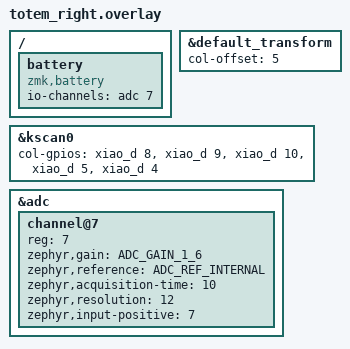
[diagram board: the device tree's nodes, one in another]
/*
 * Copyright (c) 2022 The ZMK Contributors
 *
 * SPDX-License-Identifier: MIT
 */

#include "totem.dtsi"

&default_transform {
    col-offset = <5>;
};

&kscan0 {
    col-gpios
        = <&xiao_d 8 GPIO_ACTIVE_HIGH>
        , <&xiao_d 9 GPIO_ACTIVE_HIGH>
        , <&xiao_d 10 GPIO_ACTIVE_HIGH>
        , <&xiao_d 5 GPIO_ACTIVE_HIGH>
        , <&xiao_d 4 GPIO_ACTIVE_HIGH>
        ;
};

/ {
  battery {
    compatible = "zmk,battery";
    io-channels = <&adc 7>;
  };
};

&adc {
  status = "okay";

  #address-cells = <1>;
  #size-cells = <0>;

  channel@7 {
    reg = <7>;

    /* REQUIRED by nordic,nrf-saadc */
    zephyr,gain = "ADC_GAIN_1_6";
    zephyr,reference = "ADC_REF_INTERNAL";
    zephyr,acquisition-time = <10>;
    zephyr,resolution = <12>;
    zephyr,input-positive = <7>;
  };
};
